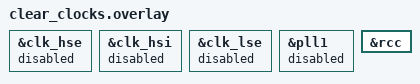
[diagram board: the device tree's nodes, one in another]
/*
 * Copyright (c) 2023 STMicroelectronics
 *
 * SPDX-License-Identifier: Apache-2.0
 */

/*
 * Warning: This overlay clears clocks back to a state equivalent to what could
 * be found in stm32wba.dtsi
 */

&clk_hse {
	status = "disabled";
	/delete-property/ hse-div;
};

&clk_hsi {
	status = "disabled";
};

&clk_lse {
	status = "disabled";
};

&pll1 {
	/delete-property/ div-m;
	/delete-property/ mul-n;
	/delete-property/ div-q;
	/delete-property/ div-r;
	/delete-property/ clocks;
	status = "disabled";
};

&rcc {
	/delete-property/ clocks;
	/delete-property/ clock-frequency;
	/delete-property/ ahb-prescaler;
	/delete-property/ ahb5-prescaler;
	/delete-property/ ahb-div;
	/delete-property/ apb1-prescaler;
	/delete-property/ apb2-prescaler;
	/delete-property/ apb7-prescaler;
};
